# MINI58DE_v1 register map
File version: 1.0
MINI58DE_v1 SVD file
Registers are 32-bit, read-write, reset 0x0 unless marked. A register's access mark holds for its fields unless they carry their own. Offsets are from the block's base; lines under a group give offsets from that group; [hi:lo] are bit positions; {n}, {i} and the like mark numbered series; 'fields as' and 'values as' point back to an identical list; <NAME> marks a mode.

## Memory map
0x40004000 WDT size 0x8 — WDT Register Map
0x40004100 WWDT size 0x10 — WWDT Register Map
0x40010000 TMR blocks up to offset 0x3C — TMR Register Map
0x40020000 I2C0 blocks up to offset 0x44 — I2C Register Map
0x40030000 SPI blocks up to offset 0x48 — SPI Register Map
0x40040000 PWM0 blocks up to offset 0x90 — PWM0 Register Map
0x40050000 UART0 size 0x34 — UART Register Map
0x400D0000 ACMP size 0x10 — ACMP Register Map
0x400E0000 ADC blocks up to offset 0x58 — ADC Register Map
0x40120000 I2C1 blocks up to offset 0x44 — I2C Register Map
0x40150000 UART1 blocks up to offset 0x34 — UART Register Map
0x50000000 SYS blocks up to offset 0x104 — SYS Register Map
0x50000200 CLK size 0x28 — CLK Register Map
0x50000300 INT size 0x88 — INT Register Map
0x50004000 GP blocks up to offset 0x2B8 — GPIO Register Map
0x5000C000 FMC blocks up to offset 0x44 — FMC Register Map
0xE000E000 SCS blocks up to offset 0xD24 — SCS Register Map

## WWDT — WWDT Register Map
Base 0x40004100
0x00 WWDT_RLDCNT wo — WWDT Reload Counter Register
  [31:0] RLDCNT — WWDT Reload Counter Register. Writing 0x00005AA5 to this register will reload the WWDT counter value to 0x3F. Note: User can only write WWDT_RLDCNT register to reload WWDT counter value when current WWDT counter value between 0 and CMPDAT (WWDT_CTL[21:16]). If user writes WWDT_RLDCNT when current WWDT counter value is larger than CMPDAT, WWDT reset signal will generate immediately.
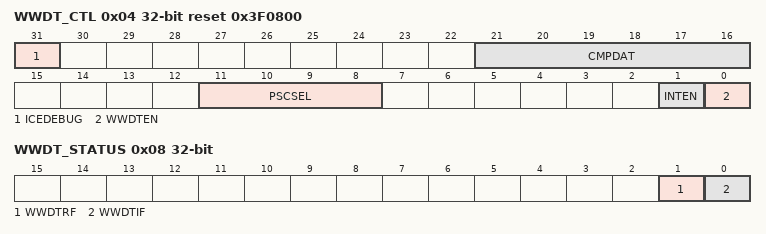
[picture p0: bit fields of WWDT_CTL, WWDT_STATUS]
0x04 WWDT_CTL reset 0x3F0800 — WWDT Control Register
  [31] ICEDEBUG — ICE Debug Mode Acknowledge Disable Bit. WWDT down counter will keep going no matter CPU is held by ICE or not.
    0=ICE debug mode acknowledgement effects WWDT counting; 1=ICE debug mode acknowledgement Disabled
  [21:16] CMPDAT — WWDT Window Compare Bits. Set this register to adjust the valid reload window. Note: User can only write WWDT_RLDCNT register to reload WWDT counter value when current WWDT counter value between 0 and CMPDAT. If user writes WWDT_RLDCNT register when current WWDT counter value larger than CMPDAT, WWDT reset signal will generate immediately.
  [11:8] PSCSEL — WWDT Counter Prescale Period Select Bits
    0=Pre-scale is 1; Max time-out period is 1 * 64 * WWDT_CLK; 1=Pre-scale is 2; Max time-out period is 2 * 64 * WWDT_CLK; 2=Pre-scale is 4; Max time-out period is 4 * 64 * WWDT_CLK; 3=Pre-scale is 8; Max time-out period is 8 * 64 * WWDT_CLK; 4=Pre-scale is 16; Max time-out period is 16 * 64 * WWDT_CLK; 5=Pre-scale is 32; Max time-out period is 32 * 64 * WWDT_CLK; 6=Pre-scale is 64; Max time-out period is 64 * 64 * WWDT_CLK; 7=Pre-scale is 128; Max time-out period is 128 * 64 * WWDT_CLK; 8=Pre-scale is 192; Max time-out period is 192 * 64 * WWDT_CLK; 9=Pre-scale is 256; Max time-out period is 256 * 64 * WWDT_CLK; 10=Pre-scale is 384; Max time-out period is 384 * 64 * WWDT_CLK; 11=Pre-scale is 512; Max time-out period is 512 * 64 * WWDT_CLK; 12=Pre-scale is 768; Max time-out period is 768 * 64 * WWDT_CLK; 13=Pre-scale is 1024; Max time-out period is 1024 * 64 * WWDT_CLK; 14=Pre-scale is 1536; Max time-out period is 1536 * 64 * WWDT_CLK; 15=Pre-scale is 2048; Max time-out period is 2048 * 64 * WWDT_CLK
  [1] INTEN — WWDT Interrupt Enable Bit. If this bit is enabled, the WWDT counter compare match interrupt signal is generated and inform to CPU.
    0=WWDT counter compare match interrupt Disabled; 1=WWDT counter compare match interrupt Enabled
  [0] WWDTEN — WWDT Enable Bit. Set this bit to enable WWDT counter counting.
    0=WWDT counter is stopped; 1=WWDT counter is starting counting
0x08 WWDT_STATUS
  [1] WWDTRF — WWDT Timer-out Reset Flag. This bit indicates the system has been reset by WWDT time-out reset or not. Note: This bit is cleared by writing 1 to it.
    0=WWDT time-out reset did not occur; 1=WWDT time-out reset occurred
  [0] WWDTIF — WWDT Compare Match Interrupt Flag. This bit indicates the interrupt flag status of WWDT while WWDT counter value matches CMPDAT (WWDT_CTL[21:16]). Note: This bit is cleared by writing 1 to it.
    0=No effect; 1=WWDT counter value matches CMPDAT
0x0C WWDT_CNT ro reset 0x3F — WWDT Counter Value Register
  [5:0] CNTDAT — WWDT Counter Value. CNTDAT will be updated continuously to monitor 6-bit WWDT down counter value.
